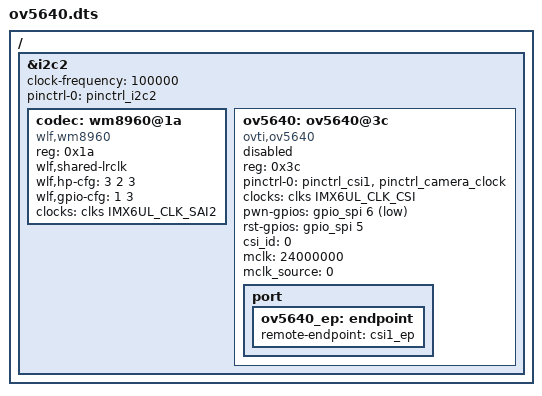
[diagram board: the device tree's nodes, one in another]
// SPDX-License-Identifier: GPL-2.0+
/*
 * Empty devicetre file for bcm7260 board
 *
 * This is required to make the board build with CONFIG OF_SEPARATE
 * In-tree document explains how to obtain a real devicetree using 'bolt' but
 * I did not attempt this.
 *
 * Copyright 2021 Google LLC
 */

// /dts-v1/;

// / {
// };

 / {
	&i2c2 {
		clock-frequency = <100000>;
		pinctrl-names = "default";
		pinctrl-0 = <&pinctrl_i2c2>;
		status = "okay";

		codec: wm8960@1a {
			#sound-dai-cells = <0>;
			compatible = "wlf,wm8960";
			reg = <0x1a>;
			wlf,shared-lrclk;
			wlf,hp-cfg = <3 2 3>;
			wlf,gpio-cfg = <1 3>;
			clocks = <&clks IMX6UL_CLK_SAI2>;
			clock-names = "mclk";
		};

		ov5640: ov5640@3c {
			compatible = "ovti,ov5640";
			reg = <0x3c>;
			pinctrl-names = "default";
			pinctrl-0 = <&pinctrl_csi1 &pinctrl_camera_clock>;
			clocks = <&clks IMX6UL_CLK_CSI>;
			clock-names = "csi_mclk";
			pwn-gpios = <&gpio_spi 6 1>;
			rst-gpios = <&gpio_spi 5 0>;
			csi_id = <0>;
			mclk = <24000000>;
			mclk_source = <0>;
			status = "disabled";
			port {
				ov5640_ep: endpoint {
					remote-endpoint = <&csi1_ep>;
				};
			};
		};

	};
};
